# NUC200AN_v1 register map
File version: 1.0
Registers are 32-bit, read-write, reset 0x0 unless marked. A register's access mark holds for its fields unless they carry their own. Offsets are from the block's base; [hi:lo] are bit positions; {n}, {i} and the like mark numbered series; 'fields as' and 'values as' point back to an identical list.

## I2C0 — I2C Register Map
Base 0x40020000
Same registers: I2C1 0x40120000
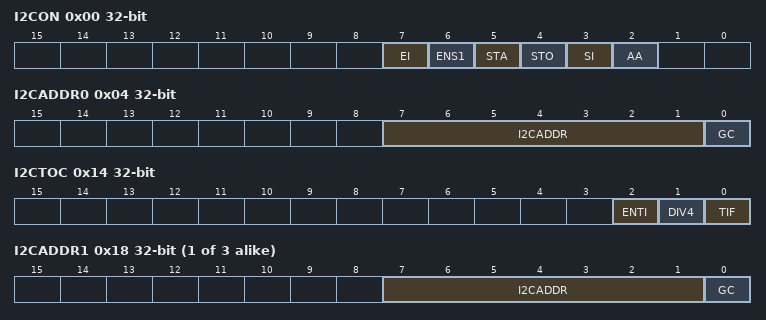
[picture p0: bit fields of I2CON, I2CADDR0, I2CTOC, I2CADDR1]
0x00 I2CON — I2C Control Register
  [7] EI — Enable Interrupt
    0=I2C interrupt Disabled; 1=I2C interrupt Enabled
  [6] ENS1 — I2C Controller Enable Bit
    0=Disabled; 1=Enabled
  [5] STA — I2C START Control Bit. Set STA to logic 1 to enter Master mode, the I2C hardware sends a START or repeat START condition to bus when the bus is free.
  [4] STO — I2C STOP Control Bit. In Master mode, set STO to transmit a STOP condition to bus then I2C hardware will check the bus condition if a STOP condition is detected this bit will be cleared by hardware automatically. In Slave mode, setting STO resets I2C hardware to the defined "not addressed" Slave mode. This means it is NO LONGER in the slave receiver mode to receive data from the master transmit device.
  [3] SI — I2C Interrupt Flag. When a new I2C state is present in the I2CSTATUS register, the SI flag is set by hardware, and if bit EI (I2CON [7]) is set, the I2C interrupt is requested. SI must be cleared by software. Clear SI is by writing 1 to this bit.
  [2] AA — Assert Acknowledge Control Bit
0x04 I2CADDR0 — I2C Slave Address Register0
  [7:1] I2CADDR — I2C Address Register. The content of this register is irrelevant when I2C is in Master mode. In Slave mode, the seven most significant bits must be loaded with the chip's own address. The I2C hardware will react if one of the addresses is matched.
  [0] GC — General Call Function
    0=General Call function Disabled; 1=General Call function Enabled
0x08 I2CDAT — I2C Data Register
  [7:0] I2CDAT — I2C Data Register. Bit [7:0] is located with the 8-bit transferred data of I2C serial port.
0x0C I2CSTATUS ro reset 0xF8
  [7:0] I2CSTATUS — I2C Status Register. The status register of I2C:
0x10 I2CLK — I2C Clock Divided Register
  [7:0] I2CLK — I2C Clock Divided Register. Note: The minimum value of I2CLK is 4.
0x14 I2CTOC — I2C Time-out Counter Register
  [2] ENTI — Time-out Counter Enable. When Enabled, the 14-bit time-out counter will start counting when SI is cleared. Writing 1 to the SI flag will reset counter and re-start up counting after SI is cleared.
    0=Time-out counter Disabled; 1=Time-out counter Enabled
  [1] DIV4 — Time-out Counter Input Clock Is Divided by 4. When Enabled, the time-out period is extended 4 times.
    0=The time-out counter input clock divided by 4 Disabled; 1=The time-out counter input clock divided by 4 Enabled
  [0] TIF — Time-out Flag. This bit is set by hardware when I2C time-out happened and it can interrupt CPU if I2C interrupt enable bit (EI) is set to 1. Software can write 1 to clear this bit.
{0x14+4i} I2CADDR{i} (i=1..3) — I2C Slave Address Register{i}
  fields as I2CADDR0
{0x24+4i} I2CADM{i} (i=0..3) — I2C Slave Address Mask Register{i}
  [7:1] I2CADM — I2C Address Mask Register. I2C bus controller supports multiple address recognition with four address mask registers. When the bit in the address mask register is set to one, it means the received corresponding address bit is don't-care. If the bit is set to 0, that means the received corresponding register bit should be exactly the same as address register.
    0=Mask Disabled (the received corresponding register bit should be exactly the same as address register.); 1=Mask Enabled (the received corresponding address bit is don't care.)
0x3C I2CWKUPCON — I2C Wake-up Control Register
  [0] WKUPEN — I2C Wake-up Function Enable
    0=I2C wake-up function Disabled; 1=I2C wake-up function Enabled
0x40 I2CWKUPSTS — I2C Wake-up Status Register
  [0] WKUPIF — I2C Wake-up Interrupt Flag. When chip is woken up from Power-down mode by I2C, this bit is set to 1. Software can write 1 to clear this bit.

## WWDT — WWDT Register Map
Base 0x40004100
0x00 WWDTRLD wo — Window Watchdog Timer Reload Counter Register
  [31:0] WWDTRLD — WWDT Reload Counter Register. Writing 0x00005AA5 to this register will reload the Window Watchdog Timer counter value to 0x3F. Note: Software can only write WWDTRLD to reload WWDT counter value when current WWDT counter value between 0 and WINCMP. If software writes WWDTRLD when current WWDT counter value is larger than WINCMP, WWDT reset signal will generate immediately.
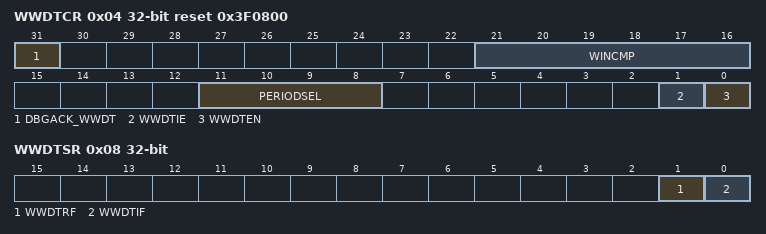
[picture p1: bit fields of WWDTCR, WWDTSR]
0x04 WWDTCR reset 0x3F0800 — Window Watchdog Timer Control Register
  [31] DBGACK_WWDT — ICE Debug Mode Acknowledge Disable
    0=WWDT counter stopped if system is in Debug mode; 1=WWDT still counted even system is in Debug mode
  [21:16] WINCMP — WWDT Window Compare Register. Set this register to adjust the valid reload window. Note: Software can only write WWDTRLD to reload WWDT counter value when current WWDT counter value between 0 and WINCMP. If Software writes WWDTRLD when current WWDT counter value larger than WINCMP, WWDT reset signal will generate immediately.
  [11:8] PERIODSEL — WWDT Prescale Period Select
  [1] WWDTIE — WWDT Interrupt Enable. Set this bit to enable the Window Watchdog Timer time-out interrupt function.
    0=WWDT time-out interrupt function Disabled if WWDTIF (WWDTSR[0] WWDT compare match interrupt flag) is 1; 1=WWDT time-out interrupt function Enabled if WWDTIF (WWDTSR[0] WWDT compare match interrupt flag) is 1
  [0] WWDTEN — WWDT Enable. Set this bit to enable Window Watchdog Timer counter counting.
    0=Window Watchdog Timer counter is stopped; 1=Window Watchdog Timer counter is starting counting
0x08 WWDTSR — Window Watchdog Timer Status Register
  [1] WWDTRF — WWDT Reset Flag. When WWDT counter counts down to 0 or writes WWDTRLD during current WWDT counter value being larger than WINCMP, chip will be reset and this bit is set to 1. This bit will be cleared to 0 by writing 1 to itself.
  [0] WWDTIF — WWDT Compare Match Interrupt Flag. When current WWDT counter value matches WWCMP, this bit is set to 1. This bit will be cleared by writing 1 to itself.
0x0C WWDTCVR ro reset 0x3F — Window Watchdog Timer Counter Value Register
  [5:0] WWDTCVAL — WWDT Counter Value. This register reflects the current WWDT counter value and is read only.

## ACMP — ACMP Register Map
Base 0x400D0000
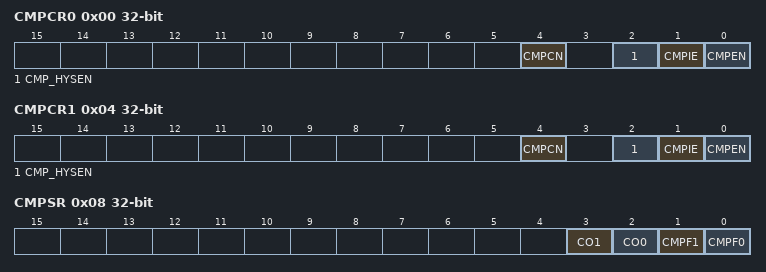
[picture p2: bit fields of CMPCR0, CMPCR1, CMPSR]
0x00 CMPCR0 — Comparator 0 Control Register
  [4] CMPCN — Comparator Negative Input Selection
    0=The source of the negative comparator input is from CMPx_N pin (x = 0, 1); 1=Internal band-gap reference voltage is selected as the source of negative comparator input
  [2] CMP_HYSEN — Comparator Hysteresis Enable
    0=Hysteresis function Disabled (Default); 1=Hysteresis function Enabled. The typical range is 20mV
  [1] CMPIE — Comparator Interrupt Enable
    0=Interrupt function Disabled; 1=Interrupt function Enabled
  [0] CMPEN — Comparator Enable. Comparator output needs to wait 2 us stable time after CMPEN is set.
    0=Disabled; 1=Enabled
0x04 CMPCR1 — Comparator 1 Control Register
  fields as CMPCR0
0x08 CMPSR — Comparator Status Register
  [3] CO1 — Comparator 1 Output
  [2] CO0 — Comparator 0 Output
  [1] CMPF1 — Comparator 1 Flag. This bit is set by hardware whenever the comparator 1 output changes state. This will cause an interrupt if CMPCR1[1] is set to 1. Write 1 to clear this bit to 0.
  [0] CMPF0 — Comparator 0 Flag. This bit is set by hardware whenever the comparator 0 output changes state. This will cause an interrupt if CMPCR0[1] is set to 1. Write 1 to clear this bit to 0.
